# KM1M7CF03 register map
Vendor: Nuvoton Technology Corporation Japan; Series: KM1M7CF; File version: 1.0.3
CPU: CM7 r1p2, little endian, MPU, FPU, double-precision FPU, I-cache, D-cache, ITCM, DTCM, 4 interrupt priority bits
Registers are 16-bit, access per field, no defined reset value unless marked. A register's access mark holds for its fields unless they carry their own. Offsets are from the block's base; [hi:lo] are bit positions; {n}, {i} and the like mark numbered series; 'fields as' and 'values as' point back to an identical list.

## INTC — Interrupt Controller
Base 0x40006000
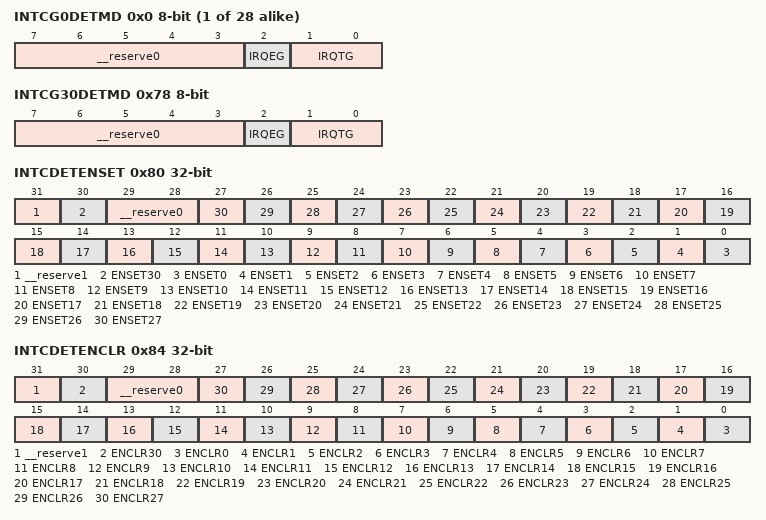
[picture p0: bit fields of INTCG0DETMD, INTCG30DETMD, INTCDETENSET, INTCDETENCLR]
{0x0+4i} INTCG{i}DETMD 8-bit rw (i=0..27) — Group {i} Interrupt Condition Specify Register
  [7:3] __reserve0 — This bit must be set to "0".
  [2] IRQEG — Both-edge detection selection
  [1:0] IRQTG — External interrupt / Comparator detection / Power supply voltage detection trigger settings
0x78 INTCG30DETMD 8-bit rw — Group 30 Interrupt Condition Specify Register
  fields as INTCG0DETMD
0x80 INTCDETENSET 32-bit rw — Condition Specification Interrupt Enable Set Register
  [31] __reserve1 — This bit must be set to "0".
  [30] ENSET30 — Group 30 interrupt enable set bit
  [29:28] __reserve0 — This bit must be set to "0".
  [n] ENSET{n} (n=0..27) — Group {n} interrupt enable set bit
0x84 INTCDETENCLR 32-bit rw — Condition Specification Interrupt Enable Clear Register
  [31] __reserve1 — This bit must be set to "0".
  [30] ENCLR30 — Group 30 interrupt enable clear bit
  [29:28] __reserve0 — This bit must be set to "0".
  [n] ENCLR{n} (n=0..27) — Group {n} interrupt enable clear bit
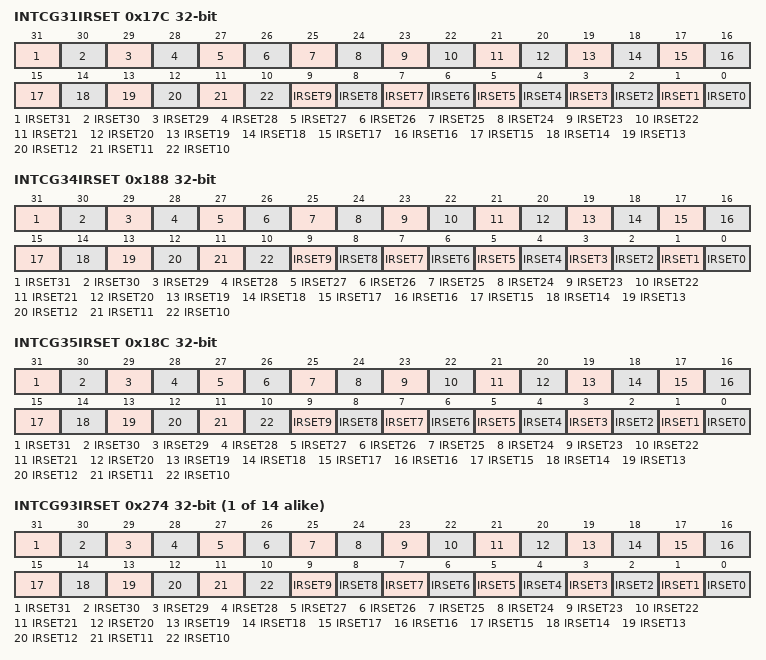
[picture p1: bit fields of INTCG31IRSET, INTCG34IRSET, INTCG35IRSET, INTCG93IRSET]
0x17C INTCG31IRSET 32-bit rw — Group 31 Interrupt Request Set Register
  [31] IRSET31 — GnIRQ No.31 interrupt request set bit
  [30] IRSET30 — GnIRQ No.30 interrupt request set bit
  [29] IRSET29 — GnIRQ No.29 interrupt request set bit
  [28] IRSET28 — GnIRQ No.28 interrupt request set bit
  [27] IRSET27 — GnIRQ No.27 interrupt request set bit
  [26] IRSET26 — GnIRQ No.26 interrupt request set bit
  [25] IRSET25 — GnIRQ No.25 interrupt request set bit
  [24] IRSET24 — GnIRQ No.24 interrupt request set bit
  [23] IRSET23 — GnIRQ No.23 interrupt request set bit
  [22] IRSET22 — GnIRQ No.22 interrupt request set bit
  [21] IRSET21 — GnIRQ No.21 interrupt request set bit
  [20] IRSET20 — GnIRQ No.20 interrupt request set bit
  [19] IRSET19 — GnIRQ No.19 interrupt request set bit
  [18] IRSET18 — GnIRQ No.18 interrupt request set bit
  [17] IRSET17 — GnIRQ No.17 interrupt request set bit
  [16] IRSET16 — GnIRQ No.16 interrupt request set bit
  [15] IRSET15 — GnIRQ No.15 interrupt request set bit
  [14] IRSET14 — GnIRQ No.14 interrupt request set bit
  [13] IRSET13 — GnIRQ No.13 interrupt request set bit
  [12] IRSET12 — GnIRQ No.12 interrupt request set bit
  [11] IRSET11 — GnIRQ No.11 interrupt request set bit
  [10] IRSET10 — GnIRQ No.10 interrupt request set bit
  [9] IRSET9 — GnIRQ No.9 interrupt request set bit
  [8] IRSET8 — GnIRQ No.8 interrupt request set bit
  [7] IRSET7 — GnIRQ No.7 interrupt request set bit
  [6] IRSET6 — GnIRQ No.6 interrupt request set bit
  [5] IRSET5 — GnIRQ No.5 interrupt request set bit
  [4] IRSET4 — GnIRQ No.4 interrupt request set bit
  [3] IRSET3 — GnIRQ No.3 interrupt request set bit
  [2] IRSET2 — GnIRQ No.2 interrupt request set bit
  [1] IRSET1 — GnIRQ No.1 interrupt request set bit
  [0] IRSET0 — GnIRQ No.0 interrupt request set bit
0x188 INTCG34IRSET 32-bit rw — Group 34 Interrupt Request Set Register
  fields as INTCG31IRSET
0x18C INTCG35IRSET 32-bit rw — Group 35 Interrupt Request Set Register
  fields as INTCG31IRSET
{0x100+4i} INTCG{i}IRSET 32-bit rw (i=93..106) — Group {i} Interrupt Request Set Register
  fields as INTCG31IRSET
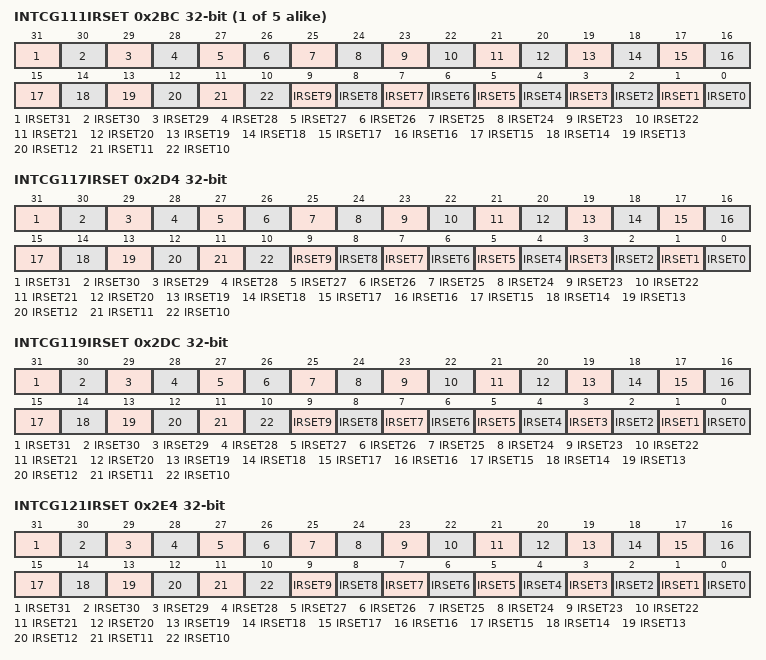
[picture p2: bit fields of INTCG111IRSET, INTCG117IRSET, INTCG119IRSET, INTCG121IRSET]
{0x100+4i} INTCG{i}IRSET 32-bit rw (i=111..115) — Group {i} Interrupt Request Set Register
  fields as INTCG31IRSET
0x2D4 INTCG117IRSET 32-bit rw — Group 117 Interrupt Request Set Register
  fields as INTCG31IRSET
0x2DC INTCG119IRSET 32-bit rw — Group 119 Interrupt Request Set Register
  fields as INTCG31IRSET
0x2E4 INTCG121IRSET 32-bit rw — Group 121 Interrupt Request Set Register
  fields as INTCG31IRSET
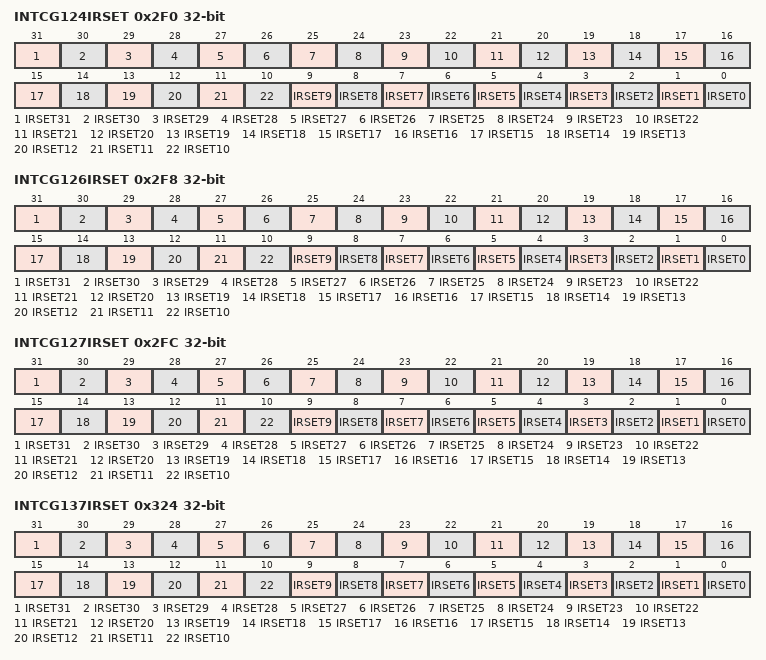
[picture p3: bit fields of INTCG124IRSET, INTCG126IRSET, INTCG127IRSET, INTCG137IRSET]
0x2F0 INTCG124IRSET 32-bit rw — Group 124 Interrupt Request Set Register
  fields as INTCG31IRSET
0x2F8 INTCG126IRSET 32-bit rw — Group 126 Interrupt Request Set Register
  fields as INTCG31IRSET
0x2FC INTCG127IRSET 32-bit rw — Group 127 Interrupt Request Set Register
  fields as INTCG31IRSET
0x324 INTCG137IRSET 32-bit rw — Group 137 Interrupt Request Set Register
  fields as INTCG31IRSET
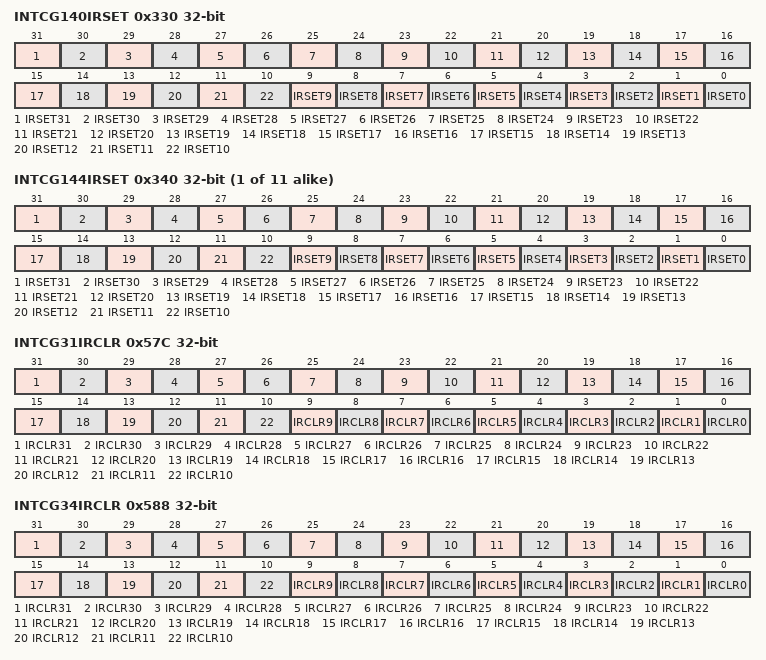
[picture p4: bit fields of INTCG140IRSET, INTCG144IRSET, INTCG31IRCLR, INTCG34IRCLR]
0x330 INTCG140IRSET 32-bit rw — Group 140 Interrupt Request Set Register
  fields as INTCG31IRSET
{0x100+4i} INTCG{i}IRSET 32-bit rw (i=144..154) — Group {i} Interrupt Request Set Register
  fields as INTCG31IRSET
0x57C INTCG31IRCLR 32-bit rw — Group 31 Interrupt Request Clear Register
  [31] IRCLR31 — GnIRQ No.31 interrupt request clear bit
  [30] IRCLR30 — GnIRQ No.30 interrupt request clear bit
  [29] IRCLR29 — GnIRQ No.29 interrupt request clear bit
  [28] IRCLR28 — GnIRQ No.28 interrupt request clear bit
  [27] IRCLR27 — GnIRQ No.27 interrupt request clear bit
  [26] IRCLR26 — GnIRQ No.26 interrupt request clear bit
  [25] IRCLR25 — GnIRQ No.25 interrupt request clear bit
  [24] IRCLR24 — GnIRQ No.24 interrupt request clear bit
  [23] IRCLR23 — GnIRQ No.23 interrupt request clear bit
  [22] IRCLR22 — GnIRQ No.22 interrupt request clear bit
  [21] IRCLR21 — GnIRQ No.21 interrupt request clear bit
  [20] IRCLR20 — GnIRQ No.20 interrupt request clear bit
  [19] IRCLR19 — GnIRQ No.19 interrupt request clear bit
  [18] IRCLR18 — GnIRQ No.18 interrupt request clear bit
  [17] IRCLR17 — GnIRQ No.17 interrupt request clear bit
  [16] IRCLR16 — GnIRQ No.16 interrupt request clear bit
  [15] IRCLR15 — GnIRQ No.15 interrupt request clear bit
  [14] IRCLR14 — GnIRQ No.14 interrupt request clear bit
  [13] IRCLR13 — GnIRQ No.13 interrupt request clear bit
  [12] IRCLR12 — GnIRQ No.12 interrupt request clear bit
  [11] IRCLR11 — GnIRQ No.11 interrupt request clear bit
  [10] IRCLR10 — GnIRQ No.10 interrupt request clear bit
  [9] IRCLR9 — GnIRQ No.9 interrupt request clear bit
  [8] IRCLR8 — GnIRQ No.8 interrupt request clear bit
  [7] IRCLR7 — GnIRQ No.7 interrupt request clear bit
  [6] IRCLR6 — GnIRQ No.6 interrupt request clear bit
  [5] IRCLR5 — GnIRQ No.5 interrupt request clear bit
  [4] IRCLR4 — GnIRQ No.4 interrupt request clear bit
  [3] IRCLR3 — GnIRQ No.3 interrupt request clear bit
  [2] IRCLR2 — GnIRQ No.2 interrupt request clear bit
  [1] IRCLR1 — GnIRQ No.1 interrupt request clear bit
  [0] IRCLR0 — GnIRQ No.0 interrupt request clear bit
0x588 INTCG34IRCLR 32-bit rw — Group 34 Interrupt Request Clear Register
  fields as INTCG31IRCLR
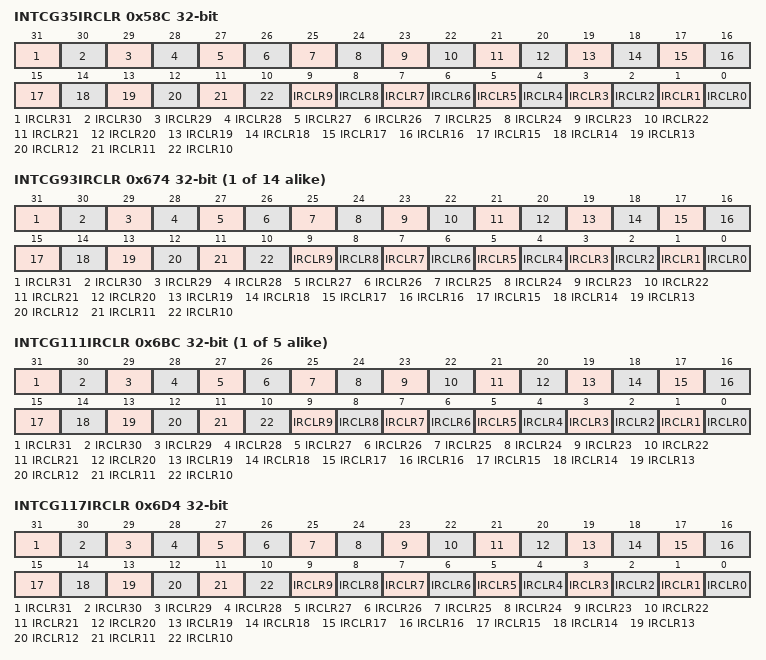
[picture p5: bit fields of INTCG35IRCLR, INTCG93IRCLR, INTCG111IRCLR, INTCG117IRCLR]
0x58C INTCG35IRCLR 32-bit rw — Group 35 Interrupt Request Clear Register
  fields as INTCG31IRCLR
{0x500+4i} INTCG{i}IRCLR 32-bit rw (i=93..106) — Group {i} Interrupt Request Clear Register
  fields as INTCG31IRCLR
{0x500+4i} INTCG{i}IRCLR 32-bit rw (i=111..115) — Group {i} Interrupt Request Clear Register
  fields as INTCG31IRCLR
0x6D4 INTCG117IRCLR 32-bit rw — Group 117 Interrupt Request Clear Register
  fields as INTCG31IRCLR
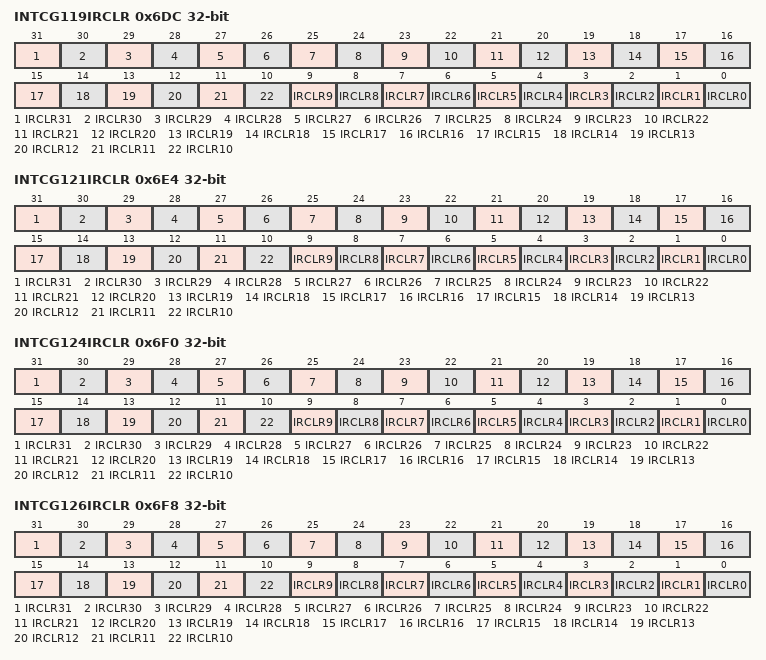
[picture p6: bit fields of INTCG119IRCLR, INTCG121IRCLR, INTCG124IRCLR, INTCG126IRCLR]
0x6DC INTCG119IRCLR 32-bit rw — Group 119 Interrupt Request Clear Register
  fields as INTCG31IRCLR
0x6E4 INTCG121IRCLR 32-bit rw — Group 121 Interrupt Request Clear Register
  fields as INTCG31IRCLR
0x6F0 INTCG124IRCLR 32-bit rw — Group 124 Interrupt Request Clear Register
  fields as INTCG31IRCLR
0x6F8 INTCG126IRCLR 32-bit rw — Group 126 Interrupt Request Clear Register
  fields as INTCG31IRCLR
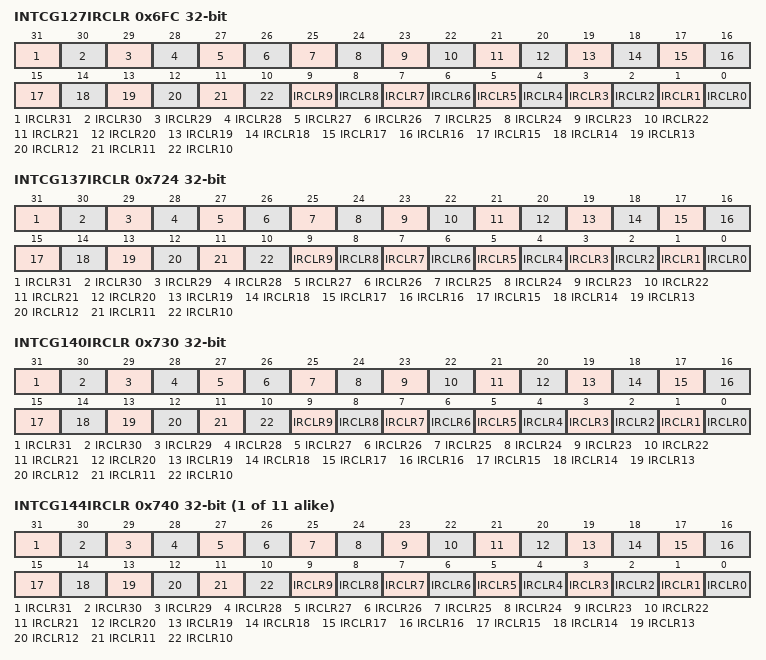
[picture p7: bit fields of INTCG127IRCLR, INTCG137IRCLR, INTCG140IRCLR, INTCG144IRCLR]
0x6FC INTCG127IRCLR 32-bit rw — Group 127 Interrupt Request Clear Register
  fields as INTCG31IRCLR
0x724 INTCG137IRCLR 32-bit rw — Group 137 Interrupt Request Clear Register
  fields as INTCG31IRCLR
0x730 INTCG140IRCLR 32-bit rw — Group 140 Interrupt Request Clear Register
  fields as INTCG31IRCLR
{0x500+4i} INTCG{i}IRCLR 32-bit rw (i=144..154) — Group {i} Interrupt Request Clear Register
  fields as INTCG31IRCLR
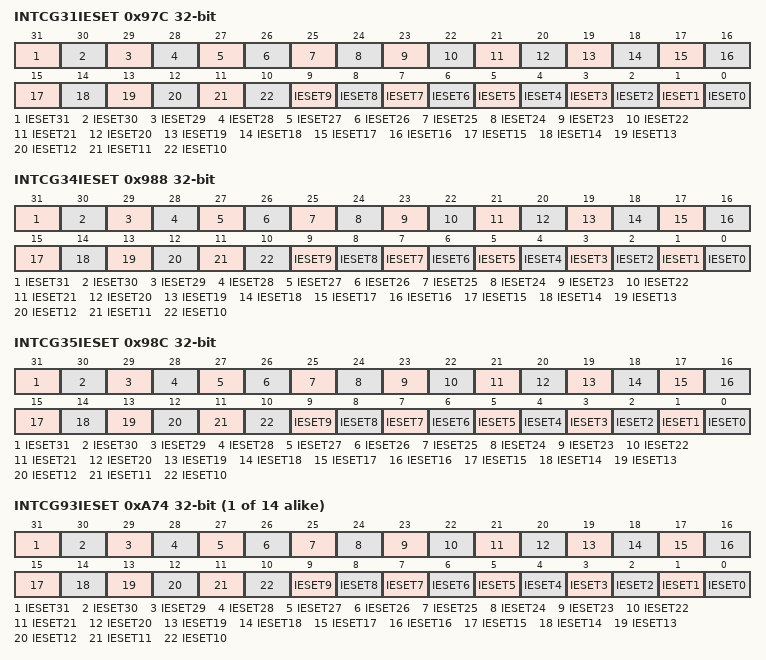
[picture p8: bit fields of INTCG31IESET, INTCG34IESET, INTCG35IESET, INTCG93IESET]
0x97C INTCG31IESET 32-bit rw — Group 31 Interrupt Enable Set Register
  [31] IESET31 — GnIRQ No.31 interrupt enable set bit
  [30] IESET30 — GnIRQ No.30 interrupt enable set bit
  [29] IESET29 — GnIRQ No.29 interrupt enable set bit
  [28] IESET28 — GnIRQ No.28 interrupt enable set bit
  [27] IESET27 — GnIRQ No.27 interrupt enable set bit
  [26] IESET26 — GnIRQ No.26 interrupt enable set bit
  [25] IESET25 — GnIRQ No.25 interrupt enable set bit
  [24] IESET24 — GnIRQ No.24 interrupt enable set bit
  [23] IESET23 — GnIRQ No.23 interrupt enable set bit
  [22] IESET22 — GnIRQ No.22 interrupt enable set bit
  [21] IESET21 — GnIRQ No.21 interrupt enable set bit
  [20] IESET20 — GnIRQ No.20 interrupt enable set bit
  [19] IESET19 — GnIRQ No.19 interrupt enable set bit
  [18] IESET18 — GnIRQ No.18 interrupt enable set bit
  [17] IESET17 — GnIRQ No.17 interrupt enable set bit
  [16] IESET16 — GnIRQ No.16 interrupt enable set bit
  [15] IESET15 — GnIRQ No.15 interrupt enable set bit
  [14] IESET14 — GnIRQ No.14 interrupt enable set bit
  [13] IESET13 — GnIRQ No.13 interrupt enable set bit
  [12] IESET12 — GnIRQ No.12 interrupt enable set bit
  [11] IESET11 — GnIRQ No.11 interrupt enable set bit
  [10] IESET10 — GnIRQ No.10 interrupt enable set bit
  [9] IESET9 — GnIRQ No.9 interrupt enable set bit
  [8] IESET8 — GnIRQ No.8 interrupt enable set bit
  [7] IESET7 — GnIRQ No.7 interrupt enable set bit
  [6] IESET6 — GnIRQ No.6 interrupt enable set bit
  [5] IESET5 — GnIRQ No.5 interrupt enable set bit
  [4] IESET4 — GnIRQ No.4 interrupt enable set bit
  [3] IESET3 — GnIRQ No.3 interrupt enable set bit
  [2] IESET2 — GnIRQ No.2 interrupt enable set bit
  [1] IESET1 — GnIRQ No.1 interrupt enable set bit
  [0] IESET0 — GnIRQ No.0 interrupt enable set bit
0x988 INTCG34IESET 32-bit rw — Group 34 Interrupt Enable Set Register
  fields as INTCG31IESET
0x98C INTCG35IESET 32-bit rw — Group 35 Interrupt Enable Set Register
  fields as INTCG31IESET
{0x900+4i} INTCG{i}IESET 32-bit rw (i=93..106) — Group {i} Interrupt Enable Set Register
  fields as INTCG31IESET
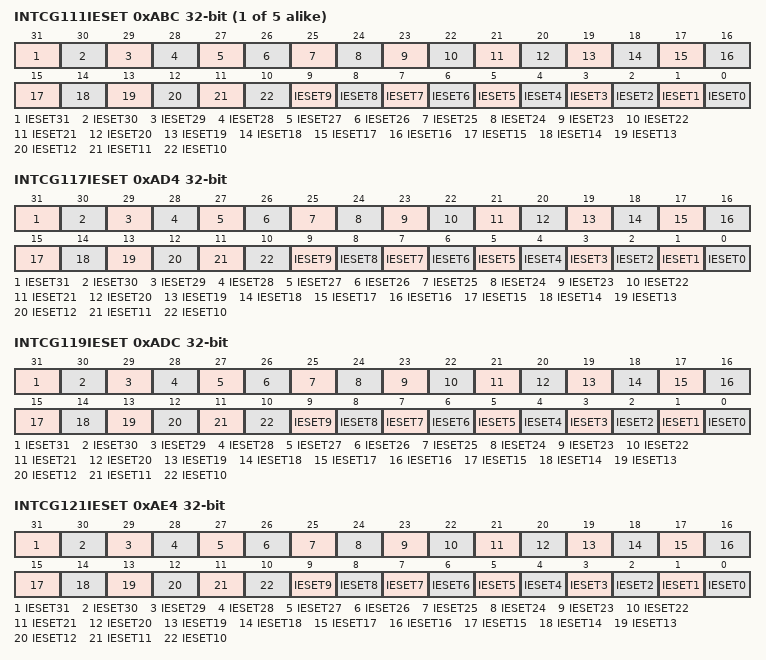
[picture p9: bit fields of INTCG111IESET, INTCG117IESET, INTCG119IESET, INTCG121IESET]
{0x900+4i} INTCG{i}IESET 32-bit rw (i=111..115) — Group {i} Interrupt Enable Set Register
  fields as INTCG31IESET
0xAD4 INTCG117IESET 32-bit rw — Group 117 Interrupt Enable Set Register
  fields as INTCG31IESET
0xADC INTCG119IESET 32-bit rw — Group 119 Interrupt Enable Set Register
  fields as INTCG31IESET
0xAE4 INTCG121IESET 32-bit rw — Group 121 Interrupt Enable Set Register
  fields as INTCG31IESET
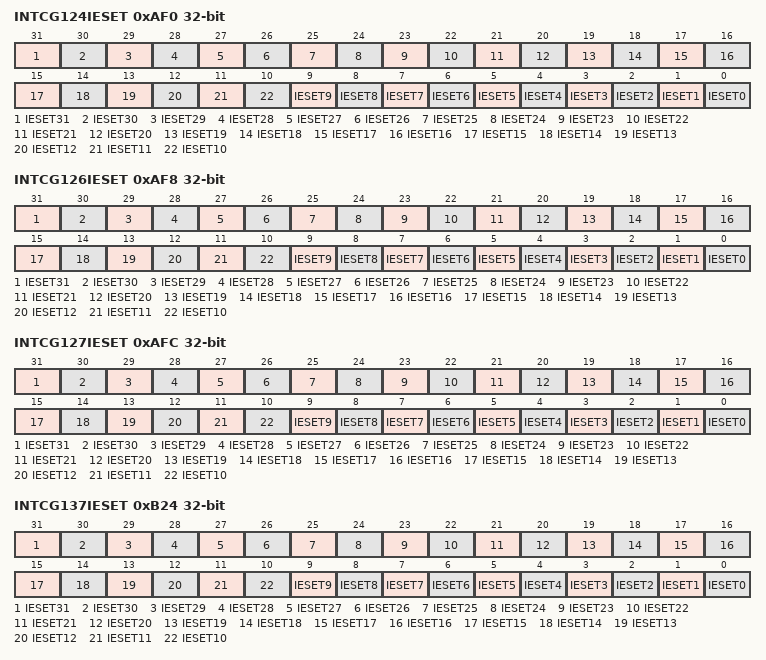
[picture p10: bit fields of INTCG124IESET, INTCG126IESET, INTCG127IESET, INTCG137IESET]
0xAF0 INTCG124IESET 32-bit rw — Group 124 Interrupt Enable Set Register
  fields as INTCG31IESET
0xAF8 INTCG126IESET 32-bit rw — Group 126 Interrupt Enable Set Register
  fields as INTCG31IESET
0xAFC INTCG127IESET 32-bit rw — Group 127 Interrupt Enable Set Register
  fields as INTCG31IESET
0xB24 INTCG137IESET 32-bit rw — Group 137 Interrupt Enable Set Register
  fields as INTCG31IESET
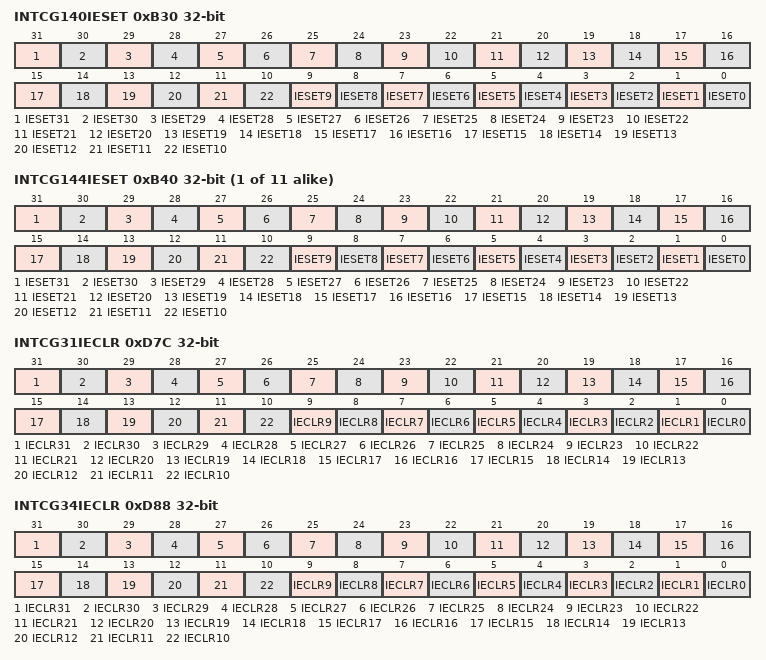
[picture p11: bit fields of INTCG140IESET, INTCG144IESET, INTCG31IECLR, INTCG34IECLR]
0xB30 INTCG140IESET 32-bit rw — Group 140 Interrupt Enable Set Register
  fields as INTCG31IESET
{0x900+4i} INTCG{i}IESET 32-bit rw (i=144..154) — Group {i} Interrupt Enable Set Register
  fields as INTCG31IESET
0xD7C INTCG31IECLR 32-bit rw — Group 31 Interrupt Enable Clear Register
  [31] IECLR31 — GnIRQ No.31 interrupt enable clear bit
  [30] IECLR30 — GnIRQ No.30 interrupt enable clear bit
  [29] IECLR29 — GnIRQ No.29 interrupt enable clear bit
  [28] IECLR28 — GnIRQ No.28 interrupt enable clear bit
  [27] IECLR27 — GnIRQ No.27 interrupt enable clear bit
  [26] IECLR26 — GnIRQ No.26 interrupt enable clear bit
  [25] IECLR25 — GnIRQ No.25 interrupt enable clear bit
  [24] IECLR24 — GnIRQ No.24 interrupt enable clear bit
  [23] IECLR23 — GnIRQ No.23 interrupt enable clear bit
  [22] IECLR22 — GnIRQ No.22 interrupt enable clear bit
  [21] IECLR21 — GnIRQ No.21 interrupt enable clear bit
  [20] IECLR20 — GnIRQ No.20 interrupt enable clear bit
  [19] IECLR19 — GnIRQ No.19 interrupt enable clear bit
  [18] IECLR18 — GnIRQ No.18 interrupt enable clear bit
  [17] IECLR17 — GnIRQ No.17 interrupt enable clear bit
  [16] IECLR16 — GnIRQ No.16 interrupt enable clear bit
  [15] IECLR15 — GnIRQ No.15 interrupt enable clear bit
  [14] IECLR14 — GnIRQ No.14 interrupt enable clear bit
  [13] IECLR13 — GnIRQ No.13 interrupt enable clear bit
  [12] IECLR12 — GnIRQ No.12 interrupt enable clear bit
  [11] IECLR11 — GnIRQ No.11 interrupt enable clear bit
  [10] IECLR10 — GnIRQ No.10 interrupt enable clear bit
  [9] IECLR9 — GnIRQ No.9 interrupt enable clear bit
  [8] IECLR8 — GnIRQ No.8 interrupt enable clear bit
  [7] IECLR7 — GnIRQ No.7 interrupt enable clear bit
  [6] IECLR6 — GnIRQ No.6 interrupt enable clear bit
  [5] IECLR5 — GnIRQ No.5 interrupt enable clear bit
  [4] IECLR4 — GnIRQ No.4 interrupt enable clear bit
  [3] IECLR3 — GnIRQ No.3 interrupt enable clear bit
  [2] IECLR2 — GnIRQ No.2 interrupt enable clear bit
  [1] IECLR1 — GnIRQ No.1 interrupt enable clear bit
  [0] IECLR0 — GnIRQ No.0 interrupt enable clear bit
0xD88 INTCG34IECLR 32-bit rw — Group 34 Interrupt Enable Clear Register
  fields as INTCG31IECLR
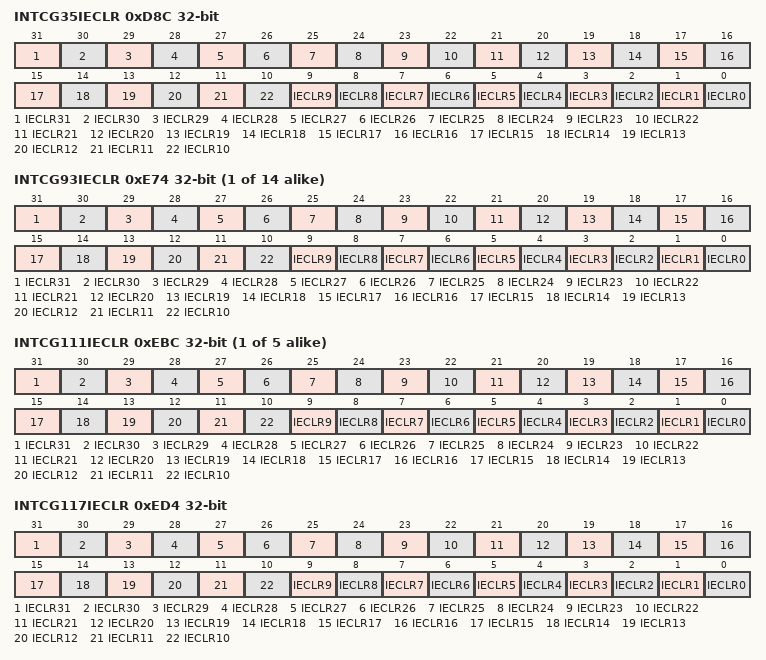
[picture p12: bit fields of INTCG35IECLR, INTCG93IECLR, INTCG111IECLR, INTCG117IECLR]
0xD8C INTCG35IECLR 32-bit rw — Group 35 Interrupt Enable Clear Register
  fields as INTCG31IECLR
{0xD00+4i} INTCG{i}IECLR 32-bit rw (i=93..106) — Group {i} Interrupt Enable Clear Register
  fields as INTCG31IECLR
{0xD00+4i} INTCG{i}IECLR 32-bit rw (i=111..115) — Group {i} Interrupt Enable Clear Register
  fields as INTCG31IECLR
0xED4 INTCG117IECLR 32-bit rw — Group 117 Interrupt Enable Clear Register
  fields as INTCG31IECLR
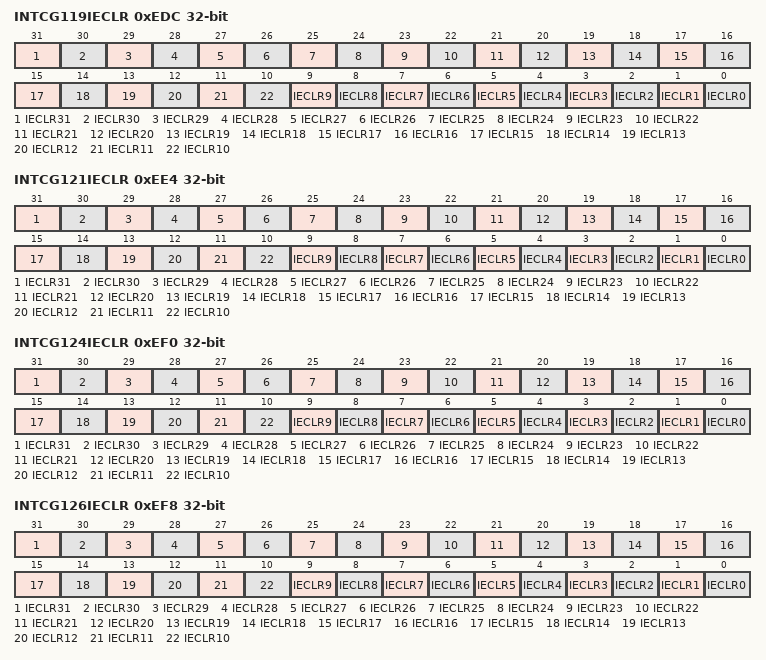
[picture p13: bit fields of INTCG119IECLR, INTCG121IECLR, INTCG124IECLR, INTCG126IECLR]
0xEDC INTCG119IECLR 32-bit rw — Group 119 Interrupt Enable Clear Register
  fields as INTCG31IECLR
0xEE4 INTCG121IECLR 32-bit rw — Group 121 Interrupt Enable Clear Register
  fields as INTCG31IECLR
0xEF0 INTCG124IECLR 32-bit rw — Group 124 Interrupt Enable Clear Register
  fields as INTCG31IECLR
0xEF8 INTCG126IECLR 32-bit rw — Group 126 Interrupt Enable Clear Register
  fields as INTCG31IECLR
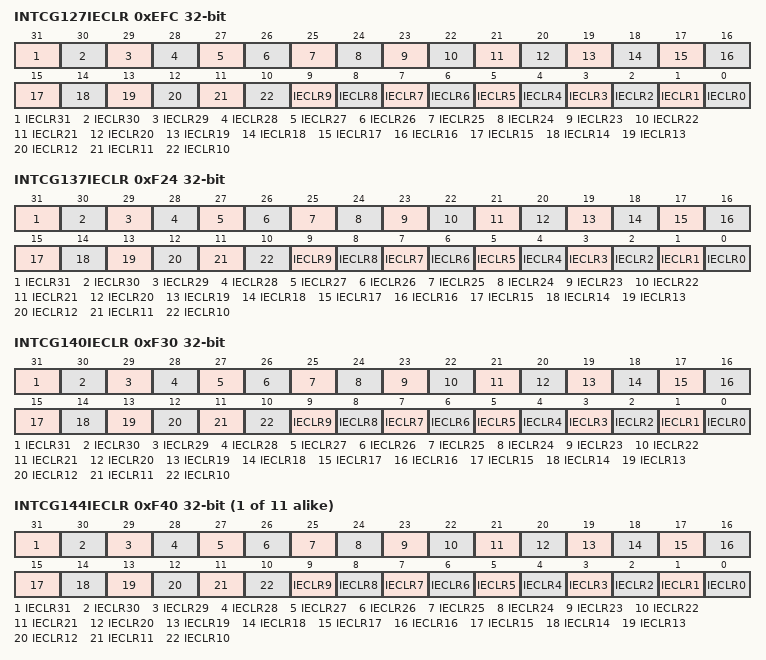
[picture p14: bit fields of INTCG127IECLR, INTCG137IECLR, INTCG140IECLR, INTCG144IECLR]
0xEFC INTCG127IECLR 32-bit rw — Group 127 Interrupt Enable Clear Register
  fields as INTCG31IECLR
0xF24 INTCG137IECLR 32-bit rw — Group 137 Interrupt Enable Clear Register
  fields as INTCG31IECLR
0xF30 INTCG140IECLR 32-bit rw — Group 140 Interrupt Enable Clear Register
  fields as INTCG31IECLR
{0xD00+4i} INTCG{i}IECLR 32-bit rw (i=144..154) — Group {i} Interrupt Enable Clear Register
  fields as INTCG31IECLR
0x117C INTCG31ID 32-bit ro — Group 31 Interrupt Detection Register
  [31] ID31 — The logical AND of GnIE[31] and GnIR[31] is read out.
  [30] ID30 — The logical AND of GnIE[30] and GnIR[30] is read out.
  [29] ID29 — The logical AND of GnIE[29] and GnIR[29] are read out.
  [n] ID{n} (n=0..28) — The logical AND of GnIE[{n}] and GnIR[{n}] is read out.
0x1188 INTCG34ID 32-bit ro — Group 34 Interrupt Detection Register
  fields as INTCG31ID
0x118C INTCG35ID 32-bit ro — Group 35 Interrupt Detection Register
  fields as INTCG31ID
{0x1100+4i} INTCG{i}ID 32-bit ro (i=93..106) — Group {i} Interrupt Detection Register
  fields as INTCG31ID
{0x1100+4i} INTCG{i}ID 32-bit ro (i=111..115) — Group {i} Interrupt Detection Register
  fields as INTCG31ID
0x12D4 INTCG117ID 32-bit ro — Group 117 Interrupt Detection Register
  fields as INTCG31ID
0x12DC INTCG119ID 32-bit ro — Group 119 Interrupt Detection Register
  fields as INTCG31ID
0x12E4 INTCG121ID 32-bit ro — Group 121 Interrupt Detection Register
  fields as INTCG31ID
0x12F0 INTCG124ID 32-bit ro — Group 124 Interrupt Detection Register
  fields as INTCG31ID
0x12F8 INTCG126ID 32-bit ro — Group 126 Interrupt Detection Register
  fields as INTCG31ID
0x12FC INTCG127ID 32-bit ro — Group 127 Interrupt Detection Register
  fields as INTCG31ID
0x1324 INTCG137ID 32-bit ro — Group 137 Interrupt Detection Register
  fields as INTCG31ID
0x1330 INTCG140ID 32-bit ro — Group 140 Interrupt Detection Register
  fields as INTCG31ID
{0x1100+4i} INTCG{i}ID 32-bit ro (i=144..154) — Group {i} Interrupt Detection Register
  fields as INTCG31ID
0x1500 INTCGNMIRSET 32-bit — Group Non-maskable Interrupt Request Set Register
  [31:2] __reserve0 ro — "0" is always read out.
  [1] IRSET1 rw — Clock error detection interrupt request set bit
  [0] IRSET0 rw — Watchdog timer error detection interrupt request set bit
0x1504 INTCGNMIRCLR 32-bit — Group Non-maskable Interrupt Request Clear Register
  [31:2] __reserve0 ro — "0" is always read out.
  [1] IRCLR1 rw — Clock error detection interrupt request clear bit
  [0] IRCLR0 rw — Watchdog timer error detection interrupt request clear bit
0x20000 PFLPSELA — Pin Protection Factor Trigger Selection Register A
  [15:8] __reserve0 ro — "0" is always read out.
  [n] IRQ{n:02}PSEL rw (n=0..7) — External interrupt {n:02} detect polarity selection
0x20002 PFLPSELB — Pin Protection Factor Trigger Selection Register B
  [15:12] __reserve0 ro — "0" is always read out.
  [11] CMP51PSEL rw — Comparator 51 detect polarity selection
  [10] CMP50PSEL rw — Comparator 50 detect polarity selection
  [9] CMP41PSEL rw — Comparator 41 detect polarity selection
  [8] CMP40PSEL rw — Comparator 40 detect polarity selection
  [7] CMP31PSEL rw — Comparator 31 detect polarity selection
  [6] CMP30PSEL rw — Comparator 30 detect polarity selection
  [5] CMP21PSEL rw — Comparator 21 detect polarity selection
  [4] CMP20PSEL rw — Comparator 20 detect polarity selection
  [3] CMP11PSEL rw — Comparator 11 detect polarity selection
  [2] CMP10PSEL rw — Comparator 10 detect polarity selection
  [1] CMP01PSEL rw — Comparator 01 detect polarity selection
  [0] CMP00PSEL rw — Comparator 00 detect polarity selection
0x20010 PFLSTATA — Pin Protection Trigger Detection Register A
  [15:14] __reserve0 ro — "0" is always read out.
  [13] AD2ERRBDET rw — Detection state of A/D2 conversion error detection B
  [12] AD2ERRADET rw — Detection state of A/D2 conversion error detection
  [11] AD1ERRBDET rw — Detection state of A/D1 conversion error detection B
  [10] AD1ERRADET rw — Detection state of A/D1 conversion error detection
  [9] AD0ERRBDET rw — Detection state of A/D0 conversion error detection B
  [8] AD0ERRADET rw — Detection state of A/D0 conversion error detection
  [n] IRQ{n:02}DET rw (n=0..7) — External interrupt {n:02} detection state
0x20012 PFLSTATB — Pin Protection Trigger Detection Register B
  [15:12] __reserve0 ro — "0" is always read out.
  [11] CMP51PSEL rw — Detection state of comparator 51 detection
  [10] CMP50PSEL rw — Detection state of comparator 50 detection
  [9] CMP41PSEL rw — Detection state of comparator 41 detection
  [8] CMP40PSEL rw — Detection state of comparator 40 detection
  [7] CMP31PSEL rw — Detection state of comparator 31 detection
  [6] CMP30PSEL rw — Detection state of comparator 30 detection
  [5] CMP21PSEL rw — Detection state of comparator 21 detection
  [4] CMP20PSEL rw — Detection state of comparator 20 detection
  [3] CMP11PSEL rw — Detection state of comparator 11 detection
  [2] CMP10PSEL rw — Detection state of comparator 10 detection
  [1] CMP01PSEL rw — Detection state of comparator 01 detection
  [0] CMP00PSEL rw — Detection state of comparator 00 detection
